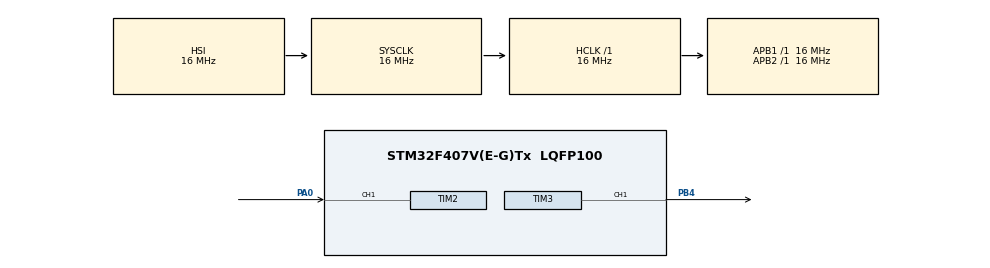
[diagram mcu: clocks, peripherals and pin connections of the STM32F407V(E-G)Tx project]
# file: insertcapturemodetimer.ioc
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Mcu.Family=STM32F4
Mcu.Name=STM32F407V(E-G)Tx
Mcu.Package=LQFP100
NVIC.PriorityGroup=NVIC_PRIORITYGROUP_4
PA0-WKUP.Signal=S_TIM2_CH1_ETR
PB4.Signal=S_TIM3_CH1
ProjectManager.HeapSize=0x200
ProjectManager.StackSize=0x400
ProjectManager.TargetToolchain=STM32CubeIDE
RCC.AHBFreq_Value=16000000
RCC.APB1Freq_Value=16000000
RCC.APB2Freq_Value=16000000
RCC.CortexFreq_Value=16000000
RCC.HSE_VALUE=25000000
RCC.HSI_VALUE=16000000
RCC.LSE_VALUE=32768
RCC.SYSCLKFreq_VALUE=16000000
RCC.VCOOutputFreq_Value=192000000
SH.S_TIM2_CH1_ETR.0=TIM2_CH1,Input_Capture1_from_TI1
SH.S_TIM3_CH1.0=TIM3_CH1,PWM Generation1 CH1
TIM2.Channel-Input_Capture1_from_TI1=TIM_CHANNEL_1
TIM2.Period=65535
TIM3.Channel-PWM\ Generation1\ CH1=TIM_CHANNEL_1
TIM3.Period=999
TIM3.Prescaler=159
board=custom

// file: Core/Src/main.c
/* USER CODE BEGIN Header */
/**
  ******************************************************************************
  * @file           : main.c
  * @brief          : Main program body
  ******************************************************************************
  * @attention
  *
  * Copyright (c) 2025 STMicroelectronics.
  * All rights reserved.
  *
  * This software is licensed under terms that can be found in the LICENSE file
  * in the root directory of this software component.
  * If no LICENSE file comes with this software, it is provided AS-IS.
  *
  ******************************************************************************
  */
/* USER CODE END Header */
#include "main.h"

TIM_HandleTypeDef htim2;
TIM_HandleTypeDef htim3;

void SystemClock_Config(void);
static void MX_GPIO_Init(void);
static void MX_TIM2_Init(void);
static void MX_TIM3_Init(void);

/* USER CODE BEGIN 0 */
uint32_t capture1 = 0;
uint32_t capture2 = 0;
uint32_t period = 0;
float frequency = 0;

/* USER CODE END 0 */

int main(void)
{

  /* MCU Configuration--------------------------------------------------------*/

  /* Reset of all peripherals, Initializes the Flash interface and the Systick. */
  HAL_Init();

  /* Configure the system clock */
  SystemClock_Config();

  /* Initialize all configured peripherals */
  MX_GPIO_Init();
  MX_TIM2_Init();
  MX_TIM3_Init();
  /* USER CODE BEGIN 2 */
  // PWM başlat (sinyal üretimi)
  HAL_TIM_PWM_Start(&htim3, TIM_CHANNEL_1);

  // Input Capture başlat
  HAL_TIM_IC_Start(&htim2, TIM_CHANNEL_1);

  /* USER CODE END 2 */

  /* Infinite loop */
  while (1)
  {
	  // İlk kenarı bekle
	  //timera bağlı pin üzerinde sinyal kenarı gelene kadar bekle
	  while (__HAL_TIM_GET_FLAG(&htim2, TIM_FLAG_CC1) == RESET);
	  //set olana kadar
	  __HAL_TIM_CLEAR_FLAG(&htim2, TIM_FLAG_CC1);
	  //bayrağı temizle tekrar beklemeye hazır ol
	  capture1 = HAL_TIM_ReadCapturedValue(&htim2, TIM_CHANNEL_1);
//o anda tuttuğu değeri oku değişkene ata
	  // İkinci kenarı bekle
	  while (__HAL_TIM_GET_FLAG(&htim2, TIM_FLAG_CC1) == RESET);
	  __HAL_TIM_CLEAR_FLAG(&htim2, TIM_FLAG_CC1);
	  capture2 = HAL_TIM_ReadCapturedValue(&htim2, TIM_CHANNEL_1);

	  // Periyot hesapla
	  if (capture2 > capture1)
	    period = capture2 - capture1;
	  else
	    period = (0xFFFF - capture1) + capture2;

	  // Frekans hesapla
	  frequency = 16000000.0 / period;

  }
}

void SystemClock_Config(void)
{
  RCC_OscInitTypeDef RCC_OscInitStruct = {0};
  RCC_ClkInitTypeDef RCC_ClkInitStruct = {0};

  /** Configure the main internal regulator output voltage
  */
  __HAL_RCC_PWR_CLK_ENABLE();
  __HAL_PWR_VOLTAGESCALING_CONFIG(PWR_REGULATOR_VOLTAGE_SCALE1);

  /** Initializes the RCC Oscillators according to the specified parameters
  * in the RCC_OscInitTypeDef structure.
  */
  RCC_OscInitStruct.OscillatorType = RCC_OSCILLATORTYPE_HSI;
  RCC_OscInitStruct.HSIState = RCC_HSI_ON;
  RCC_OscInitStruct.HSICalibrationValue = RCC_HSICALIBRATION_DEFAULT;
  RCC_OscInitStruct.PLL.PLLState = RCC_PLL_NONE;
  if (HAL_RCC_OscConfig(&RCC_OscInitStruct) != HAL_OK)
  {
    Error_Handler();
  }

  /** Initializes the CPU, AHB and APB buses clocks
  */
  RCC_ClkInitStruct.ClockType = RCC_CLOCKTYPE_HCLK|RCC_CLOCKTYPE_SYSCLK
                              |RCC_CLOCKTYPE_PCLK1|RCC_CLOCKTYPE_PCLK2;
  RCC_ClkInitStruct.SYSCLKSource = RCC_SYSCLKSOURCE_HSI;
  RCC_ClkInitStruct.AHBCLKDivider = RCC_SYSCLK_DIV1;
  RCC_ClkInitStruct.APB1CLKDivider = RCC_HCLK_DIV1;
  RCC_ClkInitStruct.APB2CLKDivider = RCC_HCLK_DIV1;

  if (HAL_RCC_ClockConfig(&RCC_ClkInitStruct, FLASH_LATENCY_0) != HAL_OK)
  {
    Error_Handler();
  }
}

static void MX_TIM2_Init(void)
{

  TIM_MasterConfigTypeDef sMasterConfig = {0};
  TIM_IC_InitTypeDef sConfigIC = {0};

  htim2.Instance = TIM2;
  htim2.Init.Prescaler = 0;
  htim2.Init.CounterMode = TIM_COUNTERMODE_UP;
  htim2.Init.Period = 65535;
  htim2.Init.ClockDivision = TIM_CLOCKDIVISION_DIV1;
  htim2.Init.AutoReloadPreload = TIM_AUTORELOAD_PRELOAD_DISABLE;
  if (HAL_TIM_IC_Init(&htim2) != HAL_OK)
  {
    Error_Handler();
  }
  sMasterConfig.MasterOutputTrigger = TIM_TRGO_RESET;
  sMasterConfig.MasterSlaveMode = TIM_MASTERSLAVEMODE_DISABLE;
  if (HAL_TIMEx_MasterConfigSynchronization(&htim2, &sMasterConfig) != HAL_OK)
  {
    Error_Handler();
  }
  sConfigIC.ICPolarity = TIM_INPUTCHANNELPOLARITY_RISING;
  sConfigIC.ICSelection = TIM_ICSELECTION_DIRECTTI;
  sConfigIC.ICPrescaler = TIM_ICPSC_DIV1;
  sConfigIC.ICFilter = 0;
  if (HAL_TIM_IC_ConfigChannel(&htim2, &sConfigIC, TIM_CHANNEL_1) != HAL_OK)
  {
    Error_Handler();
  }

}

static void MX_TIM3_Init(void)
{

  TIM_MasterConfigTypeDef sMasterConfig = {0};
  TIM_OC_InitTypeDef sConfigOC = {0};

  htim3.Instance = TIM3;
  htim3.Init.Prescaler = 159;
  htim3.Init.CounterMode = TIM_COUNTERMODE_UP;
  htim3.Init.Period = 999;
  htim3.Init.ClockDivision = TIM_CLOCKDIVISION_DIV1;
  htim3.Init.AutoReloadPreload = TIM_AUTORELOAD_PRELOAD_DISABLE;
  if (HAL_TIM_PWM_Init(&htim3) != HAL_OK)
  {
    Error_Handler();
  }
  sMasterConfig.MasterOutputTrigger = TIM_TRGO_RESET;
  sMasterConfig.MasterSlaveMode = TIM_MASTERSLAVEMODE_DISABLE;
  if (HAL_TIMEx_MasterConfigSynchronization(&htim3, &sMasterConfig) != HAL_OK)
  {
    Error_Handler();
  }
  sConfigOC.OCMode = TIM_OCMODE_PWM1;
  sConfigOC.Pulse = 0;
  sConfigOC.OCPolarity = TIM_OCPOLARITY_HIGH;
  sConfigOC.OCFastMode = TIM_OCFAST_DISABLE;
  if (HAL_TIM_PWM_ConfigChannel(&htim3, &sConfigOC, TIM_CHANNEL_1) != HAL_OK)
  {
    Error_Handler();
  }
  HAL_TIM_MspPostInit(&htim3);

}

static void MX_GPIO_Init(void)
{

  /* GPIO Ports Clock Enable */
  __HAL_RCC_GPIOA_CLK_ENABLE();
  __HAL_RCC_GPIOB_CLK_ENABLE();

}

void Error_Handler(void)
{
  __disable_irq();
  while (1)
  {
  }
}
